# STM32H7B3x register map
File version: 2.2
CPU: CM7 r0p1, little endian, MPU, FPU, 4 interrupt priority bits
Registers are 32-bit, read-write, reset 0x0 unless marked. A register's access mark holds for its fields unless they carry their own. Offsets are from the block's base; [hi:lo] are bit positions; {n}, {i} and the like mark numbered series.

## TIM16 — General-purpose-timers
Base 0x40014400
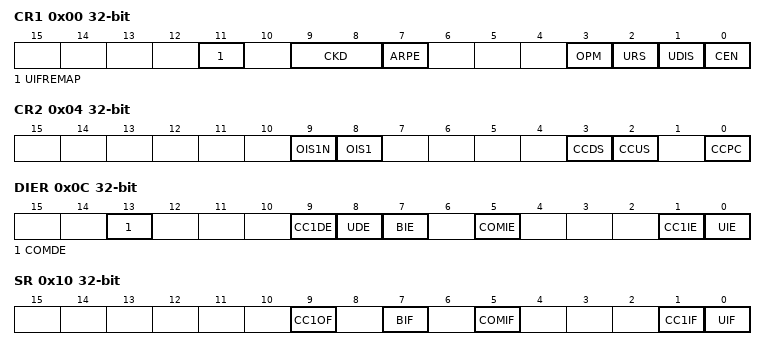
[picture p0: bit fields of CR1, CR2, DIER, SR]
0x00 CR1 — control register 1
  [11] UIFREMAP — UIF status bit remapping
  [9:8] CKD — Clock division
    0=Div1 (t_DTS = t_CK_INT); 1=Div2 (t_DTS = 2 × t_CK_INT); 2=Div4 (t_DTS = 4 × t_CK_INT)
  [7] ARPE — Auto-reload preload enable
    0=Disabled (TIMx_APRR register is not buffered); 1=Enabled (TIMx_APRR register is buffered)
  [3] OPM — One-pulse mode
    0=Disabled (Counter is not stopped at update event); 1=Enabled (Counter stops counting at the next update event (clearing the CEN bit))
  [2] URS — Update request source
    0=AnyEvent (Any of counter overflow/underflow, setting UG, or update through slave mode, generates an update interrupt or DMA request); 1=CounterOnly (Only counter overflow/underflow generates an update interrupt or DMA request)
  [1] UDIS — Update disable
    0=Enabled (Update event enabled); 1=Disabled (Update event disabled)
  [0] CEN — Counter enable
    0=Disabled (Counter disabled); 1=Enabled (Counter enabled)
0x04 CR2 — control register 2
  [9] OIS1N — Output Idle state 1
    0=Reset (OC1N=0 after a dead-time when MOE=0); 1=Set (OC1N=1 after a dead-time when MOE=0)
  [8] OIS1 — Output Idle state 1
    0=Reset (OC1=0 (after a dead-time if OC1N is implemented) when MOE=0); 1=Set (OC1=1 (after a dead-time if OC1N is implemented) when MOE=0)
  [3] CCDS — Capture/compare DMA selection
    0=OnCompare (CCx DMA request sent when CCx event occurs); 1=OnUpdate (CCx DMA request sent when update event occurs)
  [2] CCUS — Capture/compare control update selection
    0=Default (Capture/compare are updated only by setting the COMG bit); 1=WithRisingEdge (Capture/compare are updated by setting the COMG bit or when an rising edge occurs on TRGI)
  [0] CCPC — Capture/compare preloaded control
    0=NotPreloaded (CCxE, CCxNE and OCxM bits are not preloaded); 1=Preloaded (CCxE, CCxNE and OCxM bits are preloaded)
0x0C DIER — DMA/Interrupt enable register
  [13] COMDE — COM DMA request enable
  [9] CC1DE — Capture/Compare 1 DMA request enable
    0=Disabled (CC1 DMA request disabled); 1=Enabled (CC1 DMA request enabled)
  [8] UDE — Update DMA request enable
  [7] BIE — Break interrupt enable
    0=Disabled (Break interrupt disabled); 1=Enabled (Break interrupt enabled)
  [5] COMIE — COM interrupt enable
    0=Disabled (COM interrupt disabled); 1=Enabled (COM interrupt enabled)
  [1] CC1IE — Capture/Compare 1 interrupt enable
    0=Disabled (CC1 interrupt disabled); 1=Enabled (CC1 interrupt enabled)
  [0] UIE — Update interrupt enable
    0=Disabled (Update interrupt disabled); 1=Enabled (Update interrupt enabled)
0x10 SR — status register
  [9] CC1OF — Capture/Compare 1 overcapture flag
  [7] BIF — Break interrupt flag
  [5] COMIF — COM interrupt flag
  [1] CC1IF — Capture/compare 1 interrupt flag
  [0] UIF write-0-clears — Update interrupt flag
    on read: 0=NoUpdateOccurred; 1=UpdatePending (Update interrupt pending) | on write: 0=Clear flag
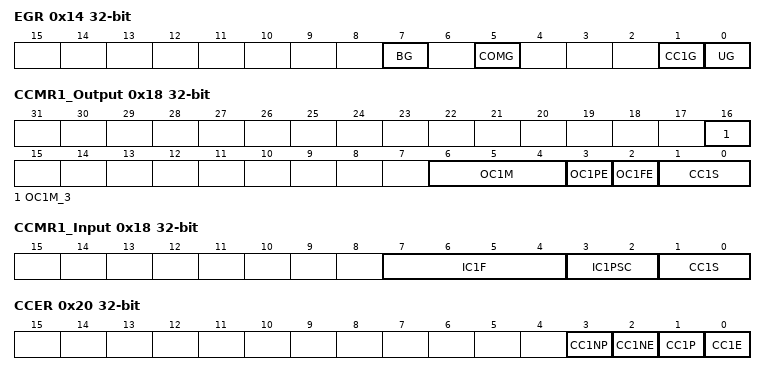
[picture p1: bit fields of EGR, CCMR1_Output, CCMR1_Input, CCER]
0x14 EGR wo — event generation register
  [7] BG — Break generation
  [5] COMG — Capture/Compare control update generation
  [1] CC1G — Capture/compare 1 generation
  [0] UG — Update generation
    on write: 1=Update (Re-initializes the timer counter and generates an update of the registers.)
0x18 CCMR1_Output — capture/compare mode register (output mode)
  [16] OC1M_3 — Output Compare 1 mode
  [6:4] OC1M — Output Compare 1 mode
    0=Frozen (The comparison between the output compare register TIMx_CCRy and the counter TIMx_CNT has no effect on the outputs); 1=ActiveOnMatch (Set channel to active level on match. OCyREF signal is forced high when the counter matches the capture/compare register); 2=InactiveOnMatch (Set channel to inactive level on match. OCyREF signal is forced low when the counter matches the capture/compare register); 3=Toggle (OCyREF toggles when TIMx_CNT=TIMx_CCRy); 4=ForceInactive (OCyREF is forced low); 5=ForceActive (OCyREF is forced high); 6=PwmMode1 (In upcounting, channel is active as long as TIMx_CNT<TIMx_CCRy else inactive. In downcounting, channel is inactive as long as TIMx_CNT>TIMx_CCRy else active); 7=PwmMode2 (Inversely to PwmMode1)
  [3] OC1PE — Output Compare 1 preload enable
    0=Disabled (Preload register on CCR1 disabled. New values written to CCR1 are taken into account immediately); 1=Enabled (Preload register on CCR1 enabled. Preload value is loaded into active register on each update event)
  [2] OC1FE — Output Compare 1 fast enable
  [1:0] CC1S — Capture/Compare 1 selection
    0=Output (CC1 channel is configured as output)
0x18 CCMR1_Input (alternate view of CCMR1_Output) — capture/compare mode register 1 (input mode)
  [7:4] IC1F — Input capture 1 filter
    0=No filter, sampling is done at fDTS; 1=FCK_INT_N2 (fSAMPLING=fCK_INT, N=2); 2=FCK_INT_N4 (fSAMPLING=fCK_INT, N=4); 3=FCK_INT_N8 (fSAMPLING=fCK_INT, N=8); 4=FDTS_Div2_N6 (fSAMPLING=fDTS/2, N=6); 5=FDTS_Div2_N8 (fSAMPLING=fDTS/2, N=8); 6=FDTS_Div4_N6 (fSAMPLING=fDTS/4, N=6); 7=FDTS_Div4_N8 (fSAMPLING=fDTS/4, N=8); 8=FDTS_Div8_N6 (fSAMPLING=fDTS/8, N=6); 9=FDTS_Div8_N8 (fSAMPLING=fDTS/8, N=8); 10=FDTS_Div16_N5 (fSAMPLING=fDTS/16, N=5); 11=FDTS_Div16_N6 (fSAMPLING=fDTS/16, N=6); 12=FDTS_Div16_N8 (fSAMPLING=fDTS/16, N=8); 13=FDTS_Div32_N5 (fSAMPLING=fDTS/32, N=5); 14=FDTS_Div32_N6 (fSAMPLING=fDTS/32, N=6); 15=FDTS_Div32_N8 (fSAMPLING=fDTS/32, N=8)
  [3:2] IC1PSC — Input capture 1 prescaler
  [1:0] CC1S — Capture/Compare 1 selection
    1=TI1 (CC1 channel is configured as input, IC1 is mapped on TI1); 2=TI2 (CC1 channel is configured as input, IC1 is mapped on TI2); 3=TRC (CC1 channel is configured as input, IC1 is mapped on TRC)
0x20 CCER — capture/compare enable register
  [3] CC1NP — Capture/Compare 1 output Polarity
  [2] CC1NE — Capture/Compare 1 complementary output enable
  [1] CC1P — Capture/Compare 1 output Polarity
  [0] CC1E — Capture/Compare 1 output enable
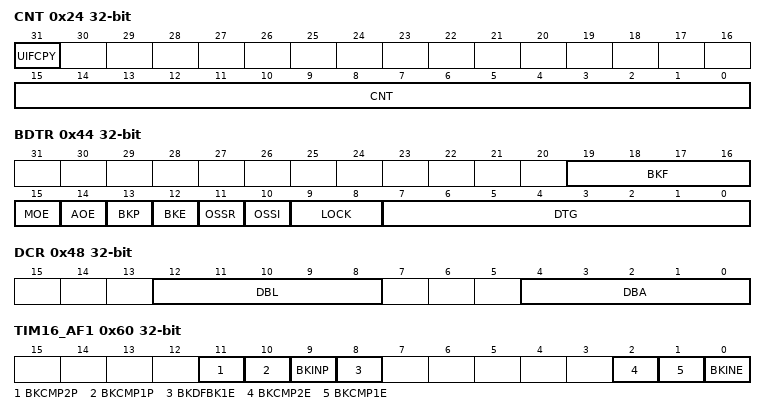
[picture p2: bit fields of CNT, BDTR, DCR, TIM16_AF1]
0x24 CNT access per field — counter
  [31] UIFCPY ro — UIF Copy
  [15:0] CNT rw — counter value
0x28 PSC — prescaler
  [15:0] PSC — Prescaler value
0x2C ARR — auto-reload register
  [15:0] ARR — Auto-reload value
0x30 RCR — repetition counter register
  [7:0] REP — Repetition counter value
0x34 CCR{i} (i=1..1; step 0x0) — capture/compare register
  [15:0] CCR — Capture/Compare 1 value
0x44 BDTR — break and dead-time register
  [19:16] BKF — Break filter
  [15] MOE — Main output enable
  [14] AOE — Automatic output enable
  [13] BKP — Break polarity
  [12] BKE — Break enable
  [11] OSSR — Off-state selection for Run mode
  [10] OSSI — Off-state selection for Idle mode
  [9:8] LOCK — Lock configuration
  [7:0] DTG — Dead-time generator setup
0x48 DCR — DMA control register
  [12:8] DBL — DMA burst length
  [4:0] DBA — DMA base address
0x4C DMAR — DMA address for full transfer
  [15:0] DMAB — DMA register for burst accesses
0x60 TIM16_AF1 — TIM16 alternate function register 1
  [11] BKCMP2P — BRK COMP2 input polarity
  [10] BKCMP1P — BRK COMP1 input polarity
  [9] BKINP — BRK BKIN input polarity
  [8] BKDFBK1E — BRK dfsdm1_break[1] enable
  [2] BKCMP2E — BRK COMP2 enable
  [1] BKCMP1E — BRK COMP1 enable
  [0] BKINE — BRK BKIN input enable
0x68 TIM16_TISEL — TIM16 input selection register
  [3:0] TI1SEL — selects TI1[0] to TI1[15] input

## TIM17 — General-purpose-timers
Base 0x40014800
Registers as TIM16 (with TIM16 read as TIM17); these are added or differ:
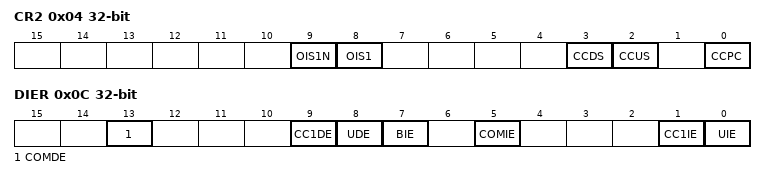
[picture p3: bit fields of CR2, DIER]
0x04 CR2 — control register 2
  [9] OIS1N — Output Idle state 1
  [8] OIS1 — Output Idle state 1
  [3] CCDS — Capture/compare DMA selection
  [2] CCUS — Capture/compare control update selection
  [0] CCPC — Capture/compare preloaded control
0x0C DIER — DMA/Interrupt enable register
  [13] COMDE — COM DMA request enable
  [9] CC1DE — Capture/Compare 1 DMA request enable
  [8] UDE — Update DMA request enable
  [7] BIE — Break interrupt enable
  [5] COMIE — COM interrupt enable
  [1] CC1IE — Capture/Compare 1 interrupt enable
  [0] UIE — Update interrupt enable
    0=Disabled (Update interrupt disabled); 1=Enabled (Update interrupt enabled)
